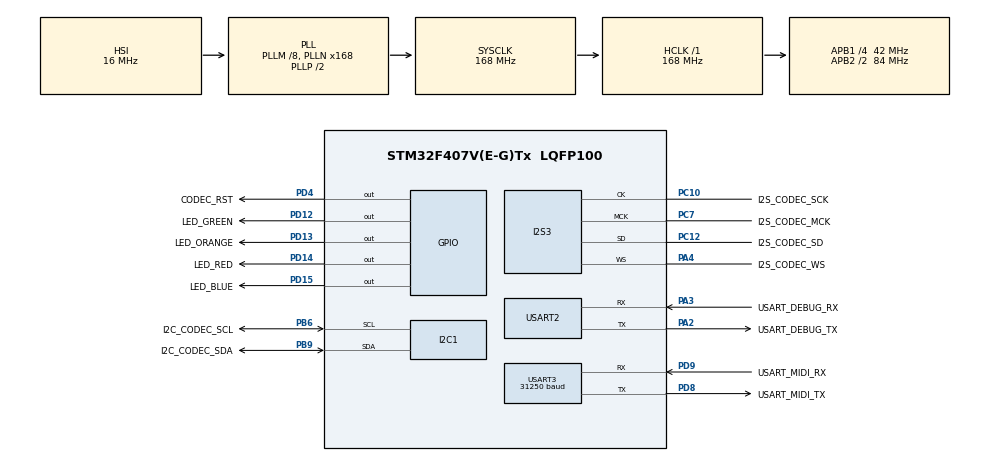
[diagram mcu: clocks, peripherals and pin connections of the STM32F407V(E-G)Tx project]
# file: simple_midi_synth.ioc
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Dma.Request0=USART3_RX
Dma.Request1=SPI3_TX
Dma.Request2=USART2_RX
Dma.Request3=USART2_TX
Dma.SPI3_TX.1.Direction=DMA_MEMORY_TO_PERIPH
Dma.SPI3_TX.1.FIFOMode=DMA_FIFOMODE_DISABLE
Dma.SPI3_TX.1.Instance=DMA1_Stream7
Dma.SPI3_TX.1.MemDataAlignment=DMA_MDATAALIGN_HALFWORD
Dma.SPI3_TX.1.MemInc=DMA_MINC_ENABLE
Dma.SPI3_TX.1.Mode=DMA_CIRCULAR
Dma.SPI3_TX.1.PeriphDataAlignment=DMA_PDATAALIGN_HALFWORD
Dma.SPI3_TX.1.PeriphInc=DMA_PINC_DISABLE
Dma.SPI3_TX.1.Priority=DMA_PRIORITY_LOW
Dma.USART2_RX.2.Direction=DMA_PERIPH_TO_MEMORY
Dma.USART2_RX.2.FIFOMode=DMA_FIFOMODE_DISABLE
Dma.USART2_RX.2.Instance=DMA1_Stream5
Dma.USART2_RX.2.MemDataAlignment=DMA_MDATAALIGN_BYTE
Dma.USART2_RX.2.MemInc=DMA_MINC_ENABLE
Dma.USART2_RX.2.Mode=DMA_NORMAL
Dma.USART2_RX.2.PeriphDataAlignment=DMA_PDATAALIGN_BYTE
Dma.USART2_RX.2.PeriphInc=DMA_PINC_DISABLE
Dma.USART2_RX.2.Priority=DMA_PRIORITY_LOW
Dma.USART2_TX.3.Direction=DMA_MEMORY_TO_PERIPH
Dma.USART2_TX.3.FIFOMode=DMA_FIFOMODE_DISABLE
Dma.USART2_TX.3.Instance=DMA1_Stream6
Dma.USART2_TX.3.MemDataAlignment=DMA_MDATAALIGN_BYTE
Dma.USART2_TX.3.MemInc=DMA_MINC_ENABLE
Dma.USART2_TX.3.Mode=DMA_NORMAL
Dma.USART2_TX.3.PeriphDataAlignment=DMA_PDATAALIGN_BYTE
Dma.USART2_TX.3.PeriphInc=DMA_PINC_DISABLE
Dma.USART2_TX.3.Priority=DMA_PRIORITY_LOW
Dma.USART3_RX.0.Direction=DMA_PERIPH_TO_MEMORY
Dma.USART3_RX.0.FIFOMode=DMA_FIFOMODE_DISABLE
Dma.USART3_RX.0.Instance=DMA1_Stream1
Dma.USART3_RX.0.MemDataAlignment=DMA_MDATAALIGN_BYTE
Dma.USART3_RX.0.MemInc=DMA_MINC_ENABLE
Dma.USART3_RX.0.Mode=DMA_NORMAL
Dma.USART3_RX.0.PeriphDataAlignment=DMA_PDATAALIGN_BYTE
Dma.USART3_RX.0.PeriphInc=DMA_PINC_DISABLE
Dma.USART3_RX.0.Priority=DMA_PRIORITY_LOW
I2S3.AudioFreq=I2S_AUDIOFREQ_48K
I2S3.ErrorAudioFreq=-2.34 %
I2S3.FullDuplexMode=I2S_FULLDUPLEXMODE_DISABLE
I2S3.Instance=SPI$Index
I2S3.RealAudioFreq=46.875 KHz
I2S3.VirtualMode=I2S_MODE_MASTER
Mcu.Family=STM32F4
Mcu.Name=STM32F407V(E-G)Tx
Mcu.Package=LQFP100
NVIC.DMA1_Stream1_IRQn=true\:0\:0\:false\:false\:true\:false\:true\:true
NVIC.DMA1_Stream5_IRQn=true\:0\:0\:false\:false\:true\:false\:true\:true
NVIC.DMA1_Stream6_IRQn=true\:0\:0\:false\:false\:true\:false\:true\:true
NVIC.DMA1_Stream7_IRQn=true\:0\:0\:false\:false\:true\:false\:true\:true
NVIC.PriorityGroup=NVIC_PRIORITYGROUP_4
NVIC.SPI3_IRQn=true\:0\:0\:false\:false\:true\:true\:true\:true
NVIC.USART2_IRQn=true\:0\:0\:false\:false\:true\:false\:true\:true
NVIC.USART3_IRQn=true\:0\:0\:false\:false\:true\:true\:true\:true
PA13.Mode=Serial_Wire
PA13.Signal=SYS_JTMS-SWDIO
PA14.Mode=Serial_Wire
PA14.Signal=SYS_JTCK-SWCLK
PA2.GPIO_Label=USART_DEBUG_TX
PA2.Mode=Asynchronous
PA2.Signal=USART2_TX
PA3.GPIO_Label=USART_DEBUG_RX
PA3.Mode=Asynchronous
PA3.Signal=USART2_RX
PA4.GPIO_Label=I2S_CODEC_WS
PA4.Mode=Half_Duplex_Master
PA4.Signal=I2S3_WS
PB6.GPIO_Label=I2C_CODEC_SCL
PB6.Mode=I2C
PB6.Signal=I2C1_SCL
PB9.GPIO_Label=I2C_CODEC_SDA
PB9.Mode=I2C
PB9.Signal=I2C1_SDA
PC10.GPIO_Label=I2S_CODEC_SCK
PC10.Mode=Half_Duplex_Master
PC10.Signal=I2S3_CK
PC12.GPIO_Label=I2S_CODEC_SD
PC12.Mode=Half_Duplex_Master
PC12.Signal=I2S3_SD
PC7.GPIO_Label=I2S_CODEC_MCK
PC7.Mode=Master_Clock_Activated
PC7.Signal=I2S3_MCK
PD12.GPIO_Label=LED_GREEN
PD12.Signal=GPIO_Output
PD13.GPIO_Label=LED_ORANGE
PD13.Signal=GPIO_Output
PD14.GPIO_Label=LED_RED
PD14.Signal=GPIO_Output
PD15.GPIO_Label=LED_BLUE
PD15.Signal=GPIO_Output
PD4.GPIO_Label=CODEC_RST
PD4.Signal=GPIO_Output
PD8.GPIO_Label=USART_MIDI_TX
PD8.Mode=Asynchronous
PD8.Signal=USART3_TX
PD9.GPIO_Label=USART_MIDI_RX
PD9.Mode=Asynchronous
PD9.Signal=USART3_RX
PH0-OSC_IN.Mode=HSE-External-Oscillator
PH0-OSC_IN.Signal=RCC_OSC_IN
PH1-OSC_OUT.Mode=HSE-External-Oscillator
PH1-OSC_OUT.Signal=RCC_OSC_OUT
ProjectManager.HeapSize=0x200
ProjectManager.StackSize=0x400
ProjectManager.TargetToolchain=Makefile
RCC.48MHZClocksFreq_Value=84000000
RCC.AHBFreq_Value=168000000
RCC.APB1CLKDivider=RCC_HCLK_DIV4
RCC.APB1Freq_Value=42000000
RCC.APB1TimFreq_Value=84000000
RCC.APB2CLKDivider=RCC_HCLK_DIV2
RCC.APB2Freq_Value=84000000
RCC.APB2TimFreq_Value=168000000
RCC.CortexFreq_Value=168000000
RCC.HCLKFreq_Value=168000000
RCC.HSE_VALUE=8000000
RCC.HSI_VALUE=16000000
RCC.LSE_VALUE=32768
RCC.PLLM=8
RCC.PLLN=168
RCC.SYSCLKFreq_VALUE=168000000
RCC.SYSCLKSource=RCC_SYSCLKSOURCE_PLLCLK
RCC.VCOOutputFreq_Value=336000000
USART2.VirtualMode=VM_ASYNC
USART3.BaudRate=31250
USART3.Mode=MODE_RX
USART3.VirtualMode=VM_ASYNC
board=custom

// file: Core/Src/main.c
/* USER CODE BEGIN Header */
/**
  ******************************************************************************
  * @file           : main.c
  * @brief          : Main program body
  ******************************************************************************
  * @attention
  *
  * Copyright (c) 2024 STMicroelectronics.
  * All rights reserved.
  *
  * This software is licensed under terms that can be found in the LICENSE file
  * in the root directory of this software component.
  * If no LICENSE file comes with this software, it is provided AS-IS.
  *
  ******************************************************************************
  */
/* USER CODE END Header */
#include "main.h"

/* USER CODE BEGIN Includes */
#include "UserMain.h"

#include <stdio.h>
/* USER CODE END Includes */

I2C_HandleTypeDef hi2c1;

I2S_HandleTypeDef hi2s3;
DMA_HandleTypeDef hdma_spi3_tx;

UART_HandleTypeDef huart2;
UART_HandleTypeDef huart3;
DMA_HandleTypeDef hdma_usart2_rx;
DMA_HandleTypeDef hdma_usart2_tx;
DMA_HandleTypeDef hdma_usart3_rx;

void SystemClock_Config(void);
static void MX_GPIO_Init(void);
static void MX_DMA_Init(void);
static void MX_I2C1_Init(void);
static void MX_USART3_UART_Init(void);
static void MX_I2S3_Init(void);
static void MX_USART2_UART_Init(void);

int main(void)
{

  /* MCU Configuration--------------------------------------------------------*/

  /* Reset of all peripherals, Initializes the Flash interface and the Systick. */
  HAL_Init();

  /* Configure the system clock */
  SystemClock_Config();

  /* Initialize all configured peripherals */
  MX_GPIO_Init();
  MX_DMA_Init();
  MX_I2C1_Init();
  MX_USART3_UART_Init();
  MX_I2S3_Init();
  MX_USART2_UART_Init();
  /* USER CODE BEGIN 2 */
  User_Init();
  /* USER CODE END 2 */

  /* Infinite loop */
  /* USER CODE BEGIN WHILE */
  while (1)
  {
    User_Main();
    /* USER CODE END WHILE */

  }
}

void SystemClock_Config(void)
{
  RCC_OscInitTypeDef RCC_OscInitStruct = {0};
  RCC_ClkInitTypeDef RCC_ClkInitStruct = {0};

  /** Configure the main internal regulator output voltage
  */
  __HAL_RCC_PWR_CLK_ENABLE();
  __HAL_PWR_VOLTAGESCALING_CONFIG(PWR_REGULATOR_VOLTAGE_SCALE1);

  /** Initializes the RCC Oscillators according to the specified parameters
  * in the RCC_OscInitTypeDef structure.
  */
  RCC_OscInitStruct.OscillatorType = RCC_OSCILLATORTYPE_HSI;
  RCC_OscInitStruct.HSIState = RCC_HSI_ON;
  RCC_OscInitStruct.HSICalibrationValue = RCC_HSICALIBRATION_DEFAULT;
  RCC_OscInitStruct.PLL.PLLState = RCC_PLL_ON;
  RCC_OscInitStruct.PLL.PLLSource = RCC_PLLSOURCE_HSI;
  RCC_OscInitStruct.PLL.PLLM = 8;
  RCC_OscInitStruct.PLL.PLLN = 168;
  RCC_OscInitStruct.PLL.PLLP = RCC_PLLP_DIV2;
  RCC_OscInitStruct.PLL.PLLQ = 4;
  if (HAL_RCC_OscConfig(&RCC_OscInitStruct) != HAL_OK)
  {
    Error_Handler();
  }

  /** Initializes the CPU, AHB and APB buses clocks
  */
  RCC_ClkInitStruct.ClockType = RCC_CLOCKTYPE_HCLK|RCC_CLOCKTYPE_SYSCLK
                              |RCC_CLOCKTYPE_PCLK1|RCC_CLOCKTYPE_PCLK2;
  RCC_ClkInitStruct.SYSCLKSource = RCC_SYSCLKSOURCE_PLLCLK;
  RCC_ClkInitStruct.AHBCLKDivider = RCC_SYSCLK_DIV1;
  RCC_ClkInitStruct.APB1CLKDivider = RCC_HCLK_DIV4;
  RCC_ClkInitStruct.APB2CLKDivider = RCC_HCLK_DIV2;

  if (HAL_RCC_ClockConfig(&RCC_ClkInitStruct, FLASH_LATENCY_5) != HAL_OK)
  {
    Error_Handler();
  }
}

static void MX_I2C1_Init(void)
{

  hi2c1.Instance = I2C1;
  hi2c1.Init.ClockSpeed = 100000;
  hi2c1.Init.DutyCycle = I2C_DUTYCYCLE_2;
  hi2c1.Init.OwnAddress1 = 0;
  hi2c1.Init.AddressingMode = I2C_ADDRESSINGMODE_7BIT;
  hi2c1.Init.DualAddressMode = I2C_DUALADDRESS_DISABLE;
  hi2c1.Init.OwnAddress2 = 0;
  hi2c1.Init.GeneralCallMode = I2C_GENERALCALL_DISABLE;
  hi2c1.Init.NoStretchMode = I2C_NOSTRETCH_DISABLE;
  if (HAL_I2C_Init(&hi2c1) != HAL_OK)
  {
    Error_Handler();
  }

}

static void MX_I2S3_Init(void)
{

  hi2s3.Instance = SPI3;
  hi2s3.Init.Mode = I2S_MODE_MASTER_TX;
  hi2s3.Init.Standard = I2S_STANDARD_PHILIPS;
  hi2s3.Init.DataFormat = I2S_DATAFORMAT_16B;
  hi2s3.Init.MCLKOutput = I2S_MCLKOUTPUT_ENABLE;
  hi2s3.Init.AudioFreq = I2S_AUDIOFREQ_48K;
  hi2s3.Init.CPOL = I2S_CPOL_LOW;
  hi2s3.Init.ClockSource = I2S_CLOCK_PLL;
  hi2s3.Init.FullDuplexMode = I2S_FULLDUPLEXMODE_DISABLE;
  if (HAL_I2S_Init(&hi2s3) != HAL_OK)
  {
    Error_Handler();
  }

}

static void MX_USART2_UART_Init(void)
{

  huart2.Instance = USART2;
  huart2.Init.BaudRate = 115200;
  huart2.Init.WordLength = UART_WORDLENGTH_8B;
  huart2.Init.StopBits = UART_STOPBITS_1;
  huart2.Init.Parity = UART_PARITY_NONE;
  huart2.Init.Mode = UART_MODE_TX_RX;
  huart2.Init.HwFlowCtl = UART_HWCONTROL_NONE;
  huart2.Init.OverSampling = UART_OVERSAMPLING_16;
  if (HAL_UART_Init(&huart2) != HAL_OK)
  {
    Error_Handler();
  }

}

static void MX_USART3_UART_Init(void)
{

  huart3.Instance = USART3;
  huart3.Init.BaudRate = 31250;
  huart3.Init.WordLength = UART_WORDLENGTH_8B;
  huart3.Init.StopBits = UART_STOPBITS_1;
  huart3.Init.Parity = UART_PARITY_NONE;
  huart3.Init.Mode = UART_MODE_RX;
  huart3.Init.HwFlowCtl = UART_HWCONTROL_NONE;
  huart3.Init.OverSampling = UART_OVERSAMPLING_16;
  if (HAL_UART_Init(&huart3) != HAL_OK)
  {
    Error_Handler();
  }

}

static void MX_DMA_Init(void)
{

  /* DMA controller clock enable */
  __HAL_RCC_DMA1_CLK_ENABLE();

  /* DMA interrupt init */
  /* DMA1_Stream1_IRQn interrupt configuration */
  HAL_NVIC_SetPriority(DMA1_Stream1_IRQn, 0, 0);
  HAL_NVIC_EnableIRQ(DMA1_Stream1_IRQn);
  /* DMA1_Stream5_IRQn interrupt configuration */
  HAL_NVIC_SetPriority(DMA1_Stream5_IRQn, 0, 0);
  HAL_NVIC_EnableIRQ(DMA1_Stream5_IRQn);
  /* DMA1_Stream6_IRQn interrupt configuration */
  HAL_NVIC_SetPriority(DMA1_Stream6_IRQn, 0, 0);
  HAL_NVIC_EnableIRQ(DMA1_Stream6_IRQn);
  /* DMA1_Stream7_IRQn interrupt configuration */
  HAL_NVIC_SetPriority(DMA1_Stream7_IRQn, 0, 0);
  HAL_NVIC_EnableIRQ(DMA1_Stream7_IRQn);

}

static void MX_GPIO_Init(void)
{
  GPIO_InitTypeDef GPIO_InitStruct = {0};

  /* GPIO Ports Clock Enable */
  __HAL_RCC_GPIOH_CLK_ENABLE();
  __HAL_RCC_GPIOA_CLK_ENABLE();
  __HAL_RCC_GPIOD_CLK_ENABLE();
  __HAL_RCC_GPIOC_CLK_ENABLE();
  __HAL_RCC_GPIOB_CLK_ENABLE();

  /*Configure GPIO pin Output Level */
  HAL_GPIO_WritePin(GPIOD, LED_GREEN_Pin|LED_ORANGE_Pin|LED_RED_Pin|LED_BLUE_Pin
                          |CODEC_RST_Pin, GPIO_PIN_RESET);

  /*Configure GPIO pins : LED_GREEN_Pin LED_ORANGE_Pin LED_RED_Pin LED_BLUE_Pin
                           CODEC_RST_Pin */
  GPIO_InitStruct.Pin = LED_GREEN_Pin|LED_ORANGE_Pin|LED_RED_Pin|LED_BLUE_Pin
                          |CODEC_RST_Pin;
  GPIO_InitStruct.Mode = GPIO_MODE_OUTPUT_PP;
  GPIO_InitStruct.Pull = GPIO_NOPULL;
  GPIO_InitStruct.Speed = GPIO_SPEED_FREQ_LOW;
  HAL_GPIO_Init(GPIOD, &GPIO_InitStruct);

}

/* USER CODE BEGIN 4 */
#ifdef __GNUC__
#define PUTCHAR_PROTOTYPE int __io_putchar(int ch)
#else
#define PUTCHAR_PROTOTYPE int fputc(int ch, FILE *f)
#endif /* __GNUC__ */

/**
  * @brief  Retargets the C library printf function to the USART.
  * @param  None
  * @retval None
  */
PUTCHAR_PROTOTYPE
{
    HAL_UART_Transmit(&huart2, (uint8_t *)&ch, 1, HAL_MAX_DELAY);
    return ch;
}
/* USER CODE END 4 */

void Error_Handler(void)
{
  __disable_irq();
  while (1)
  {
  }
}
